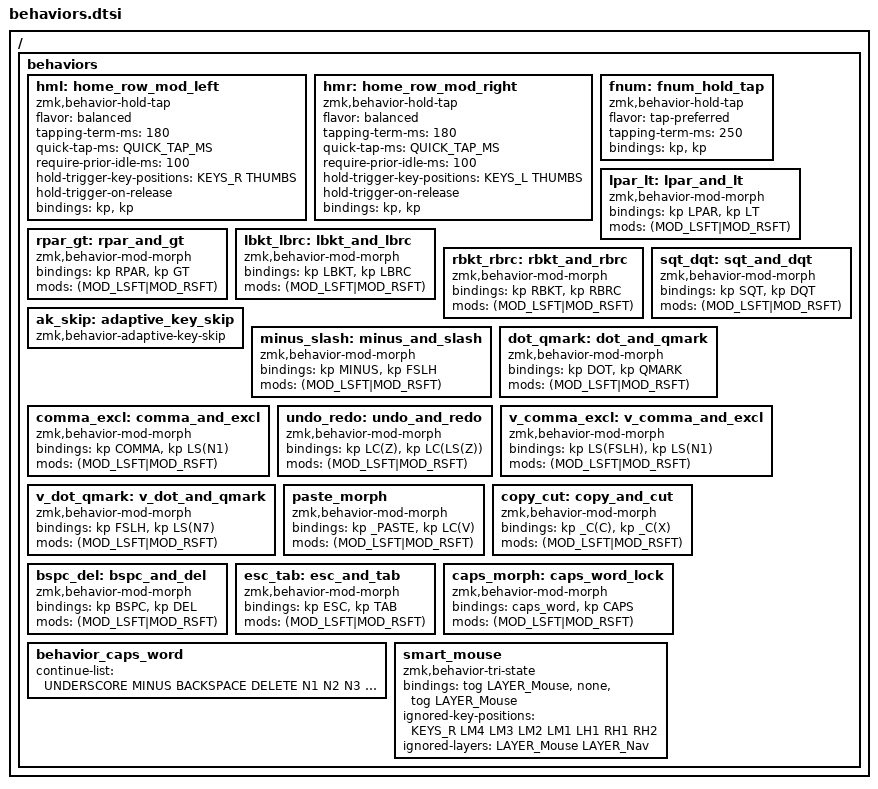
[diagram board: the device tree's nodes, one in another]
/ {
    behaviors {
        hml: home_row_mod_left {
            compatible = "zmk,behavior-hold-tap";
            #binding-cells = <2>;
            flavor = "balanced";
            tapping-term-ms = <180>;
            quick-tap-ms = <QUICK_TAP_MS>;
            require-prior-idle-ms = <100>;
            hold-trigger-key-positions = <KEYS_R THUMBS>;
            hold-trigger-on-release;
            bindings = <&kp>, <&kp>;
        };

        hmr: home_row_mod_right {
            compatible = "zmk,behavior-hold-tap";
            #binding-cells = <2>;
            flavor = "balanced";
            tapping-term-ms = <180>;
            quick-tap-ms = <QUICK_TAP_MS>;
            require-prior-idle-ms = <100>;
            hold-trigger-key-positions = <KEYS_L THUMBS>;
            hold-trigger-on-release;
            bindings = <&kp>, <&kp>;
        };

        fnum: fnum_hold_tap {
            compatible = "zmk,behavior-hold-tap";
            #binding-cells = <2>;
            flavor = "tap-preferred";
            tapping-term-ms = <250>;
            bindings = <&kp>, <&kp>;
        };

        lpar_lt: lpar_and_lt {
            compatible = "zmk,behavior-mod-morph";
            #binding-cells = <0>;
            bindings = <&kp LPAR>, <&kp LT>;
            mods = <(MOD_LSFT|MOD_RSFT)>;
        };

        rpar_gt: rpar_and_gt {
            compatible = "zmk,behavior-mod-morph";
            #binding-cells = <0>;
            bindings = <&kp RPAR>, <&kp GT>;
            mods = <(MOD_LSFT|MOD_RSFT)>;
        };

        lbkt_lbrc: lbkt_and_lbrc {
            compatible = "zmk,behavior-mod-morph";
            #binding-cells = <0>;
            bindings = <&kp LBKT>, <&kp LBRC>;
            mods = <(MOD_LSFT|MOD_RSFT)>;
        };

        rbkt_rbrc: rbkt_and_rbrc {
            compatible = "zmk,behavior-mod-morph";
            #binding-cells = <0>;
            bindings = <&kp RBKT>, <&kp RBRC>;
            mods = <(MOD_LSFT|MOD_RSFT)>;
        };

        sqt_dqt: sqt_and_dqt {
            compatible = "zmk,behavior-mod-morph";
            #binding-cells = <0>;
            bindings = <&kp SQT>, <&kp DQT>;
            mods = <(MOD_LSFT|MOD_RSFT)>;
        };

        ak_skip: adaptive_key_skip {
            compatible = "zmk,behavior-adaptive-key-skip";
            #binding-cells = <0>;
        };

        minus_slash: minus_and_slash {
            compatible = "zmk,behavior-mod-morph";
            #binding-cells = <0>;
            bindings = <&kp MINUS>, <&kp FSLH>;
            mods = <(MOD_LSFT|MOD_RSFT)>;
        };

        dot_qmark: dot_and_qmark {
            compatible = "zmk,behavior-mod-morph";
            #binding-cells = <0>;
            bindings = <&kp DOT>, <&kp QMARK>;
            mods = <(MOD_LSFT|MOD_RSFT)>;
        };

        comma_excl: comma_and_excl {
            compatible = "zmk,behavior-mod-morph";
            #binding-cells = <0>;
            bindings = <&kp COMMA>, <&kp LS(N1)>;
            mods = <(MOD_LSFT|MOD_RSFT)>;
        };

        undo_redo: undo_and_redo {
            compatible = "zmk,behavior-mod-morph";
            #binding-cells = <0>;
            bindings = <&kp LC(Z)>, <&kp LC(LS(Z))>;
            mods = <(MOD_LSFT|MOD_RSFT)>;
        };

        v_comma_excl: v_comma_and_excl {
            compatible = "zmk,behavior-mod-morph";
            #binding-cells = <0>;
            bindings = <&kp LS(FSLH)>, <&kp LS(N1)>;
            mods = <(MOD_LSFT|MOD_RSFT)>;
        };

        v_dot_qmark: v_dot_and_qmark {
            compatible = "zmk,behavior-mod-morph";
            #binding-cells = <0>;
            bindings = <&kp FSLH>, <&kp LS(N7)>;
            mods = <(MOD_LSFT|MOD_RSFT)>;
        };

        paste_morph: paste_morph {
            compatible = "zmk,behavior-mod-morph";
            #binding-cells = <0>;
            bindings = <&kp _PASTE>, <&kp LC(V)>;
            mods = <(MOD_LSFT|MOD_RSFT)>;
        };

        copy_cut: copy_and_cut {
            compatible = "zmk,behavior-mod-morph";
            #binding-cells = <0>;
            bindings = <&kp _C(C)>, <&kp _C(X)>;
            mods = <(MOD_LSFT|MOD_RSFT)>;
        };

        bspc_del: bspc_and_del {
            compatible = "zmk,behavior-mod-morph";
            #binding-cells = <0>;
            bindings = <&kp BSPC>, <&kp DEL>;
            mods = <(MOD_LSFT|MOD_RSFT)>;
        };

        esc_tab: esc_and_tab {
            compatible = "zmk,behavior-mod-morph";
            #binding-cells = <0>;
            bindings = <&kp ESC>, <&kp TAB>;
            mods = <(MOD_LSFT|MOD_RSFT)>;
        };

        caps_morph: caps_word_lock {
            compatible = "zmk,behavior-mod-morph";
            #binding-cells = <0>;
            bindings = <&caps_word>, <&kp CAPS>;
            mods = <(MOD_LSFT|MOD_RSFT)>;
        };

        behavior_caps_word {
            continue-list = <
                UNDERSCORE MINUS
                BACKSPACE DELETE
                N1 N2 N3 N4 N5 N6 N7 N8 N9 N0
            >;
        };
    };
};

ZMK_TRI_STATE(smart_mouse,
    bindings = <&tog LAYER_Mouse>, <&none>, <&tog LAYER_Mouse>;
    ignored-key-positions = <KEYS_R LM4 LM3 LM2 LM1 LH1 RH1 RH2>;
    ignored-layers = <LAYER_Mouse LAYER_Nav>;
)
